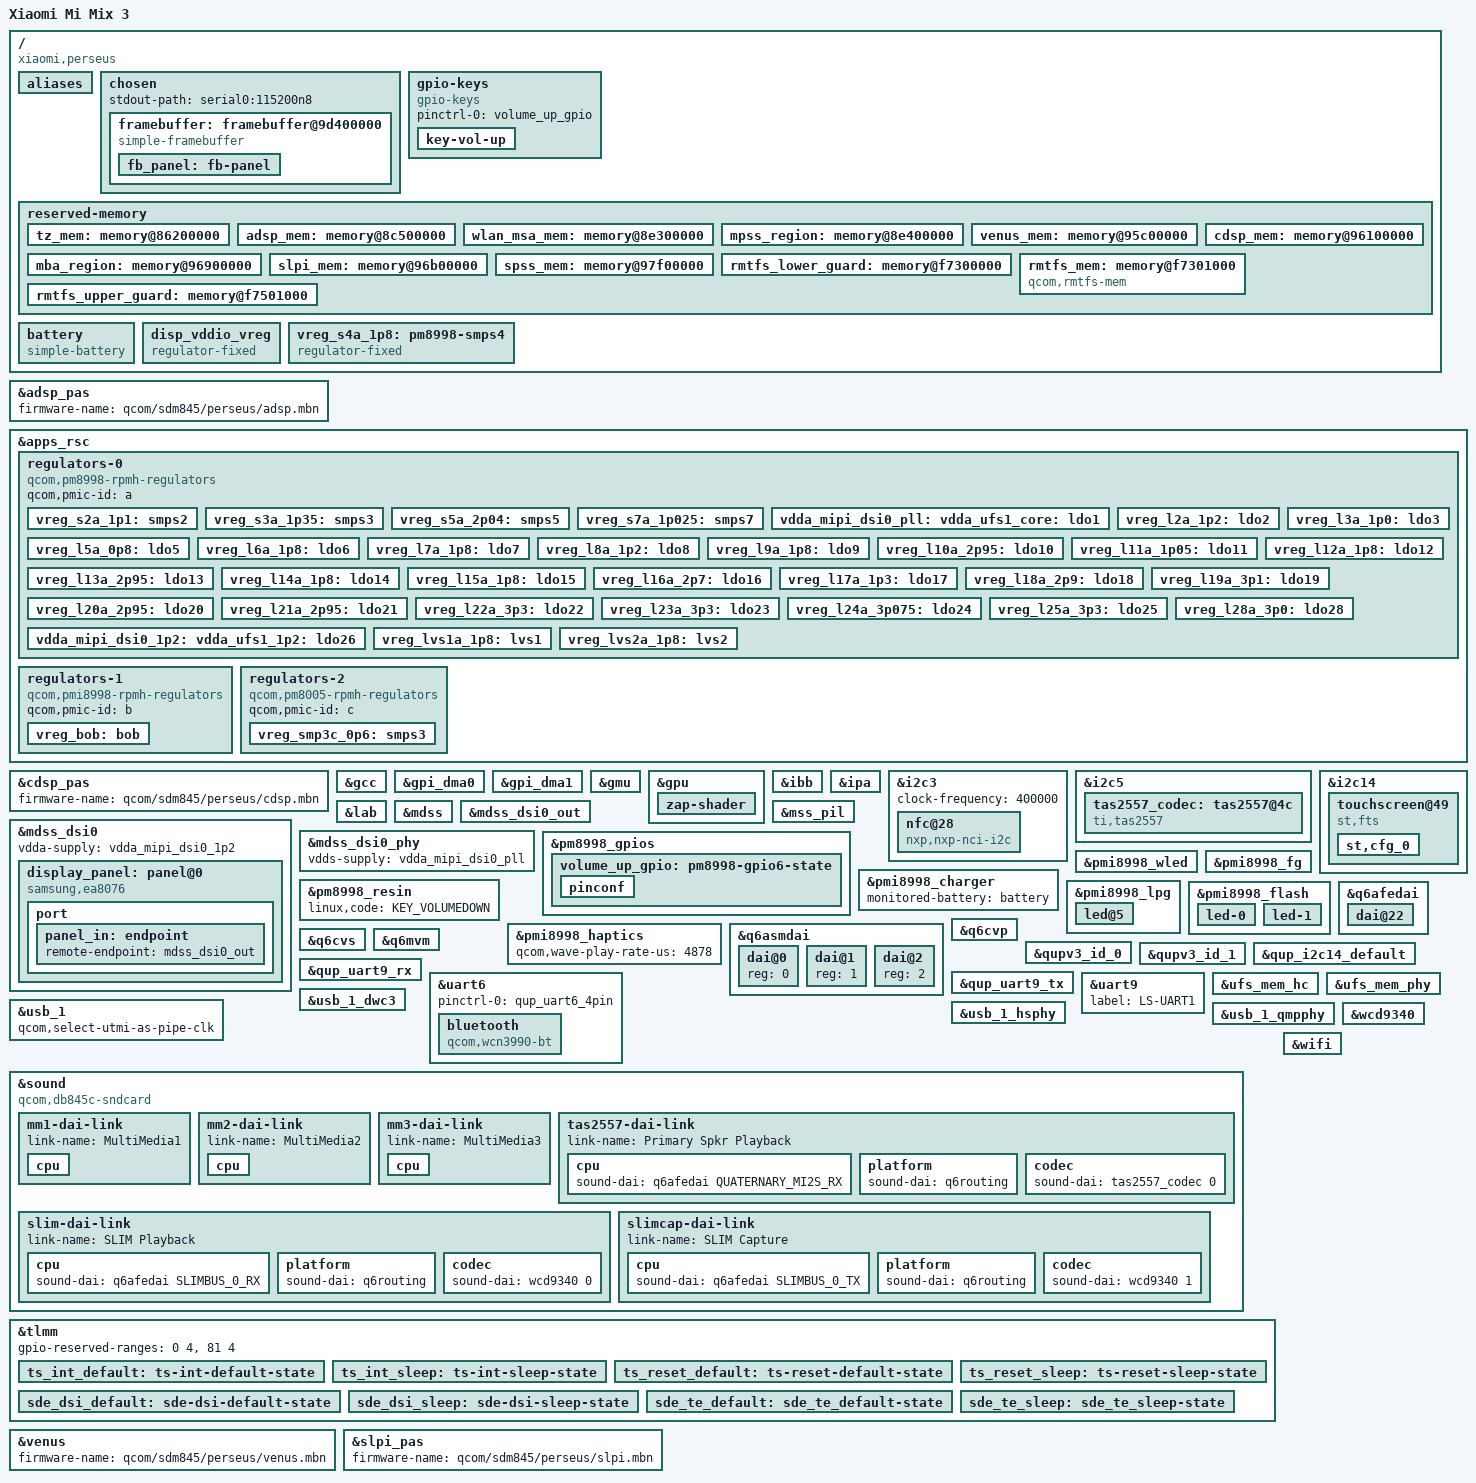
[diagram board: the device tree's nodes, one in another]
// SPDX-License-Identifier: GPL-2.0

/dts-v1/;

#include <dt-bindings/leds/common.h>
#include <dt-bindings/media/video-interfaces.h>
#include <dt-bindings/gpio/gpio.h>
#include <dt-bindings/pinctrl/qcom,pmic-gpio.h>
#include <dt-bindings/regulator/qcom,rpmh-regulator.h>
#include <dt-bindings/input/linux-event-codes.h>
#include <dt-bindings/sound/qcom,q6afe.h>
#include <dt-bindings/sound/qcom,q6asm.h>
#include <dt-bindings/sound/qcom,q6afe.h>
#include <dt-bindings/sound/qcom,q6asm.h>
#include <dt-bindings/sound/qcom,q6voice.h>

#include "sdm845.dtsi"
#include "sdm845-wcd9340.dtsi"
#include "pm8998.dtsi"
#include "pmi8998.dtsi"
#include "pm8005.dtsi"

/*
* Delete following upstream (sdm845.dtsi) reserved
* memory mappings which are different in this device.
*/
/delete-node/ &tz_mem;
/delete-node/ &adsp_mem;
/delete-node/ &wlan_msa_mem;
/delete-node/ &mpss_region;
/delete-node/ &venus_mem;
/delete-node/ &cdsp_mem;
/delete-node/ &mba_region;
/delete-node/ &slpi_mem;
/delete-node/ &spss_mem;
/delete-node/ &rmtfs_mem;

/{
	model = "Xiaomi Mi Mix 3";
	compatible = "xiaomi,perseus", "qcom,sdm845";
	chassis-type = "handset";

	/* required for bootloader to select correct board */
	qcom,board-id = <0x63 0x0>;
	qcom,msm-id = <0x141 0x20001>;

	aliases {
		serial0 = &uart9;
		serial1 = &uart6;
	};

	chosen {
		#address-cells = <2>;
		#size-cells = <2>;
		ranges;

		stdout-path = "serial0:115200n8";

		framebuffer: framebuffer@9d400000 {
			compatible = "simple-framebuffer";
			reg = <0 0x9D400000 0 0x2400000>;
			width = <1080>;
			height = <2340>;
			stride = <(1080 * 4)>;
			format = "a8r8g8b8";
			status = "okay";

			panel = <&fb_panel>;

			fb_panel: fb-panel {
				width-mm = <68>;
				height-mm = <147>;
			};
		};
	};

	gpio-keys {
		compatible = "gpio-keys";

		pinctrl-names = "default";
		pinctrl-0 = <&volume_up_gpio>;

		key-vol-up {
			label = "Volume up";
			linux,code = <KEY_VOLUMEUP>;
			gpios = <&pm8998_gpios 6 GPIO_ACTIVE_LOW>;
		};
	};

	reserved-memory {
		tz_mem: memory@86200000 {
			reg = <0 0x86200000 0 0x4900000>;
			no-map;
		};

		adsp_mem: memory@8c500000 {
			reg = <0 0x8c500000 0 0x1e00000>;
			no-map;
		};

		wlan_msa_mem: memory@8e300000 {
			reg = <0 0x8e300000 0 0x100000>;
			no-map;
		};

		mpss_region: memory@8e400000 {
			reg = <0 0x8e400000 0 0x7800000>;
			no-map;
		};

		venus_mem: memory@95c00000 {
			reg = <0 0x95c00000 0 0x500000>;
			no-map;
		};

		cdsp_mem: memory@96100000 {
			reg = <0 0x96100000 0 0x800000>;
			no-map;
		};

		mba_region: memory@96900000 {
			reg = <0 0x96900000 0 0x200000>;
			no-map;
		};

		slpi_mem: memory@96b00000 {
			reg = <0 0x96b00000 0 0x1400000>;
			no-map;
		};

		spss_mem: memory@97f00000 {
			reg = <0 0x97f00000 0 0x100000>;
			no-map;
		};

		rmtfs_lower_guard: memory@f7300000 {
			reg = <0 0xf7300000 0 0x1000>;
			no-map;
		};

		rmtfs_mem: memory@f7301000 {
			compatible = "qcom,rmtfs-mem";
			reg = <0 0xf7301000 0 0x200000>;
			no-map;

			qcom,client-id = <1>;
			qcom,vmid = <QCOM_SCM_VMID_MSS_MSA>;
		};

		rmtfs_upper_guard: memory@f7501000 {
			reg = <0 0xf7501000 0 0x1000>;
			no-map;
		};
	};

	battery: battery {
		compatible = "simple-battery";

		charge-full-design-microamp-hours = <3200000>;
		voltage-min-design-microvolt = <3700000>;
		voltage-max-design-microvolt = <4400000>;
	};

	disp_vddio_vreg: disp_vddio_vreg {
		compatible = "regulator-fixed";
		regulator-name = "disp_vddio_vreg";
		startup-delay-us = <4000>;
		regulator-always-on;
		regulator-boot-on;
		enable-active-high;
		gpio = <&tlmm 79 0>;
	};

	/*
	* Apparently RPMh does not provide support for PM8998 S4 because it
	* is always-on; model it as a fixed regulator.
	*/
	vreg_s4a_1p8: pm8998-smps4 {
		compatible = "regulator-fixed";
		regulator-name = "vreg_s4a_1p8";

		regulator-min-microvolt = <1800000>;
		regulator-max-microvolt = <1800000>;

		regulator-always-on;
	};
};

&adsp_pas {
	status = "okay";
	firmware-name = "qcom/sdm845/perseus/adsp.mbn";
};

&apps_rsc {
	regulators-0 {
		compatible = "qcom,pm8998-rpmh-regulators";
		qcom,pmic-id = "a";

		vreg_s2a_1p1: smps2 {
			regulator-always-on;
			regulator-min-microvolt = <1100000>;
			regulator-max-microvolt = <1100000>;
		};

		vreg_s3a_1p35: smps3 {
			regulator-min-microvolt = <1352000>;
			regulator-max-microvolt = <1352000>;
		};

		vreg_s5a_2p04: smps5 {
			regulator-always-on;
			regulator-min-microvolt = <1904000>;
			regulator-max-microvolt = <2040000>;
		};

		vreg_s7a_1p025: smps7 {
			regulator-always-on;
			regulator-min-microvolt = <900000>;
			regulator-max-microvolt = <1028000>;
		};

		vdda_mipi_dsi0_pll:
		vdda_ufs1_core:
		vreg_l1a_0p875: ldo1 {
			regulator-min-microvolt = <880000>;
			regulator-max-microvolt = <880000>;
			regulator-initial-mode = <RPMH_REGULATOR_MODE_HPM>;
		};

		vreg_l2a_1p2: ldo2 {
			regulator-min-microvolt = <1200000>;
			regulator-max-microvolt = <1200000>;
			regulator-initial-mode = <RPMH_REGULATOR_MODE_HPM>;
			regulator-always-on;
		};

		vreg_l3a_1p0: ldo3 {
			regulator-min-microvolt = <1000000>;
			regulator-max-microvolt = <1000000>;
			regulator-initial-mode = <RPMH_REGULATOR_MODE_HPM>;
		};

		vreg_l5a_0p8: ldo5 {
			regulator-min-microvolt = <800000>;
			regulator-max-microvolt = <800000>;
			regulator-initial-mode = <RPMH_REGULATOR_MODE_HPM>;
		};

		vreg_l6a_1p8: ldo6 {
			regulator-min-microvolt = <1856000>;
			regulator-max-microvolt = <1856000>;
			regulator-initial-mode = <RPMH_REGULATOR_MODE_HPM>;
		};

		vreg_l7a_1p8: ldo7 {
			regulator-min-microvolt = <1800000>;
			regulator-max-microvolt = <1800000>;
			regulator-initial-mode = <RPMH_REGULATOR_MODE_HPM>;
		};

		vreg_l8a_1p2: ldo8 {
			regulator-min-microvolt = <1200000>;
			regulator-max-microvolt = <1248000>;
			regulator-initial-mode = <RPMH_REGULATOR_MODE_HPM>;
		};

		vreg_l9a_1p8: ldo9 {
			regulator-min-microvolt = <1704000>;
			regulator-max-microvolt = <2928000>;
			regulator-initial-mode = <RPMH_REGULATOR_MODE_HPM>;
		};

		vreg_l10a_2p95: ldo10 {
			regulator-min-microvolt = <1704000>;
			regulator-max-microvolt = <2928000>;
			regulator-initial-mode = <RPMH_REGULATOR_MODE_HPM>;
		};

		vreg_l11a_1p05: ldo11 {
			regulator-min-microvolt = <1000000>;
			regulator-max-microvolt = <1048000>;
			regulator-initial-mode = <RPMH_REGULATOR_MODE_HPM>;
		};

		vreg_l12a_1p8: ldo12 {
			regulator-min-microvolt = <1800000>;
			regulator-max-microvolt = <1800000>;
			regulator-initial-mode = <RPMH_REGULATOR_MODE_HPM>;
		};

		vreg_l13a_2p95: ldo13 {
			regulator-min-microvolt = <1800000>;
			regulator-max-microvolt = <2960000>;
			regulator-initial-mode = <RPMH_REGULATOR_MODE_HPM>;
		};

		vreg_l14a_1p8: ldo14 {
			regulator-min-microvolt = <1800000>;
			regulator-max-microvolt = <1800000>;
			regulator-always-on;
			regulator-boot-on;
			regulator-initial-mode = <RPMH_REGULATOR_MODE_HPM>;
		};

		vreg_l15a_1p8: ldo15 {
			regulator-min-microvolt = <1800000>;
			regulator-max-microvolt = <1800000>;
			regulator-initial-mode = <RPMH_REGULATOR_MODE_HPM>;
		};

		vreg_l16a_2p7: ldo16 {
			regulator-min-microvolt = <2704000>;
			regulator-max-microvolt = <2704000>;
			regulator-initial-mode = <RPMH_REGULATOR_MODE_HPM>;
		};

		vreg_l17a_1p3: ldo17 {
			regulator-always-on;
			regulator-min-microvolt = <1304000>;
			regulator-max-microvolt = <1304000>;
			regulator-initial-mode = <RPMH_REGULATOR_MODE_HPM>;
		};

		vreg_l18a_2p9: ldo18 {
			regulator-min-microvolt = <2704000>;
			regulator-max-microvolt = <2960000>;
			regulator-initial-mode = <RPMH_REGULATOR_MODE_HPM>;
		};

		vreg_l19a_3p1: ldo19 {
			regulator-min-microvolt = <2856000>;
			regulator-max-microvolt = <3104000>;
			regulator-initial-mode = <RPMH_REGULATOR_MODE_HPM>;
		};

		vreg_l20a_2p95: ldo20 {
			regulator-min-microvolt = <2704000>;
			regulator-max-microvolt = <2960000>;
			regulator-initial-mode = <RPMH_REGULATOR_MODE_HPM>;
		};

		vreg_l21a_2p95: ldo21 {
			regulator-min-microvolt = <2704000>;
			regulator-max-microvolt = <2960000>;
			regulator-initial-mode = <RPMH_REGULATOR_MODE_HPM>;
		};

		vreg_l22a_3p3: ldo22 {
			regulator-min-microvolt = <2864000>;
			regulator-max-microvolt = <3312000>;
			regulator-initial-mode = <RPMH_REGULATOR_MODE_HPM>;
		};

		vreg_l23a_3p3: ldo23 {
			regulator-min-microvolt = <3000000>;
			regulator-max-microvolt = <3312000>;
			regulator-initial-mode = <RPMH_REGULATOR_MODE_HPM>;
		};

		vreg_l24a_3p075: ldo24 {
			regulator-min-microvolt = <3088000>;
			regulator-max-microvolt = <3088000>;
			regulator-initial-mode = <RPMH_REGULATOR_MODE_HPM>;
		};

		vreg_l25a_3p3: ldo25 {
			regulator-always-on;
			regulator-min-microvolt = <3000000>;
			regulator-max-microvolt = <3312000>;
			regulator-initial-mode = <RPMH_REGULATOR_MODE_HPM>;
		};

		vdda_mipi_dsi0_1p2:
		vdda_ufs1_1p2:
		vreg_l26a_1p2: ldo26 {
			regulator-min-microvolt = <1200000>;
			regulator-max-microvolt = <1200000>;
			regulator-initial-mode = <RPMH_REGULATOR_MODE_HPM>;
			regulator-boot-on;
		};

		vreg_l28a_3p0: ldo28 {
			regulator-min-microvolt = <2856000>;
			regulator-max-microvolt = <3008000>;
			regulator-initial-mode = <RPMH_REGULATOR_MODE_HPM>;
			regulator-always-on;
		};

		vreg_lvs1a_1p8: lvs1 {
			regulator-min-microvolt = <1800000>;
			regulator-max-microvolt = <1800000>;
			regulator-always-on;
		};

		vreg_lvs2a_1p8: lvs2 {
			regulator-min-microvolt = <1800000>;
			regulator-max-microvolt = <1800000>;
			regulator-always-on;
		};
	};

	regulators-1 {
		compatible = "qcom,pmi8998-rpmh-regulators";
		qcom,pmic-id = "b";

		vreg_bob: bob {
			regulator-min-microvolt = <3312000>;
			regulator-max-microvolt = <3600000>;
			regulator-initial-mode = <RPMH_REGULATOR_MODE_AUTO>;
			regulator-allow-bypass;
		};
	};

	regulators-2 {
		compatible = "qcom,pm8005-rpmh-regulators";
		qcom,pmic-id = "c";

		vreg_smp3c_0p6: smps3 {
			regulator-min-microvolt = <600000>;
			regulator-max-microvolt = <600000>;
		};
	};
};

&cdsp_pas {
	status = "okay";
	firmware-name = "qcom/sdm845/perseus/cdsp.mbn";
};


&gcc {
	protected-clocks = <GCC_QSPI_CORE_CLK>,
				<GCC_QSPI_CORE_CLK_SRC>,
				<GCC_QSPI_CNOC_PERIPH_AHB_CLK>,
				<GCC_LPASS_Q6_AXI_CLK>,
				<GCC_LPASS_SWAY_CLK>;
};

&gpi_dma0 {
	status = "okay";
};

&gpi_dma1 {
	status = "okay";
};

&gmu {
	status = "okay";
};

&gpu {
	status = "okay";

	zap-shader {
		memory-region = <&gpu_mem>;
		firmware-name = "qcom/sdm845/perseus/a630_zap.mbn";
	};
};

&ibb {
	regulator-min-microvolt = <4600000>;
	regulator-max-microvolt = <6000000>;
	regulator-over-current-protection;
	regulator-pull-down;
	regulator-soft-start;
	qcom,discharge-resistor-kohms = <300>;
};

&ipa {
	qcom,gsi-loader = "self";
	memory-region = <&ipa_fw_mem>;
	firmware-name = "qcom/sdm845/perseus/ipa_fws.mbn";
	status = "okay";
};

&i2c3 {
	status = "okay";
	clock-frequency = <400000>;

	nfc@28 {
		compatible = "nxp,nxp-nci-i2c";
		reg = <0x28>;

		interrupt-parent = <&tlmm>;
		interrupts = <63 IRQ_TYPE_LEVEL_HIGH>;

		enable-gpios = <&tlmm 128 GPIO_ACTIVE_HIGH>;
		firmware-gpios = <&tlmm 88 GPIO_ACTIVE_HIGH>;

		//qcom,nq-irq = <0x34 0x3f 0x00>;
		//qcom,nq-ven = <0x34 0x80 0x00>;
		//qcom,nq-firm = <0x34 0x58 0x00>;
		//qcom,nq-clkreq = <0xe6 0x15 0x00>;
		//qcom,nq-esepwr = <0x34 0x74 0x00>;
	};
};

&i2c5 {
	#dma-cells = <3>;
	status = "okay";

	dmas =  <&gpi_dma0 0 5 QCOM_GPI_I2C>,
			<&gpi_dma0 1 5 QCOM_GPI_I2C>;
	dma-names = "tx", "rx";
	tas2557_codec: tas2557@4c{
		#sound-dai-cells = <1>;
		compatible = "ti,tas2557";
		reg = <0x4c>;
		ti,cdc-reset-gpio = <&tlmm 69 0>;
		ti,irq-gpio = <&tlmm 30 0>;
		ti,i2s-bits = <16>;
		ti,bypass-tmax = <0>;
	};
};

&i2c14 {
	#dma-cells = <3>;
	status = "okay";
	clock-frequency = <400000>;

	dmas =  <&gpi_dma1 0 6 QCOM_GPI_I2C>,
			<&gpi_dma1 1 6 QCOM_GPI_I2C>;
	dma-names = "tx", "rx";

	touchscreen@49 {
		compatible = "st,fts";
		reg = <0x49>;
		interrupts-extended = <&tlmm 31 0x2008>;

		pinctrl-names = "default", "sleep";
		pinctrl-0 = <&ts_int_default &ts_reset_default>;
		pinctrl-1 = <&ts_int_sleep &ts_reset_sleep>;

		vdd-supply = <&disp_vddio_vreg>;
		avdd-supply = <&vreg_l28a_3p0>;

		st,pwr-reg-name = "avdd";
		st,bus-reg-name = "vdd";
		st,regulator_dvdd = "vdd";
		st,regulator_avdd = "avdd";
		st,irq-gpio = <&tlmm 31 0x2008>;
		st,irq-gpio-name = "fts_irq";
		st,reset-gpio-enable;
		st,reset-gpio = <&tlmm 32 0x00>;
		st,max-coords = <1079 2339>;
		st,reset-gpio-name = "fts_rst";
		st,irq-flags = <0x2008>;
		st,key-num = <2>;
		st,key-codes = <158 139>;
		st,config-array-size = <1>;
		st,default-fw-name = "st_fts_e5.ftb";

		st,cfg_0 {
			st,tp-vendor = <0x52>;
			st,fw-name = "st_fts_e5.ftb";
			st,limit-name = "stm_fts_production_limits.csv";
		};
	};
};

&lab {
	regulator-min-microvolt = <4600000>;
	regulator-max-microvolt = <6000000>;
	regulator-soft-start;
	regulator-pull-down;
};

&mdss {
	status = "okay";
};

&mdss_dsi0 {
	status = "okay";
	vdda-supply = <&vdda_mipi_dsi0_1p2>;

	#address-cells = <1>;
	#size-cells = <0>;

	display_panel: panel@0 {
		status = "okay";
		compatible = "samsung,ea8076";
		#address-cells = <1>;
		#size-cells = <0>;
		reg = <0>;

		reset-gpios = <&tlmm 6 GPIO_ACTIVE_LOW>;
		vddio-supply = <&vreg_l14a_1p8>;
		backlight = <&pmi8998_wled>;
		vddpos-supply = <&lab>;
		vddneg-supply = <&ibb>;

		pinctrl-names = "default", "sleep";
		pinctrl-0 = <&sde_dsi_default &sde_te_default>;
		pinctrl-1 = <&sde_dsi_sleep &sde_te_sleep>;

		port {
			panel_in: endpoint {
				remote-endpoint = <&mdss_dsi0_out>;
			};
		};
	};
};

&mdss_dsi0_out {
	remote-endpoint = <&panel_in>;
	data-lanes = <0 1 2 3>;
};

&mdss_dsi0_phy {
	status = "okay";
	vdds-supply = <&vdda_mipi_dsi0_pll>;
};

&mss_pil {
	status = "okay";
	firmware-name = "qcom/sdm845/perseus/mba.mbn", "qcom/sdm845/perseus/modem.mbn";
};

&pm8998_gpios {
	volume_up_gpio: pm8998-gpio6-state {
		pinconf {
			qcom,drive-strength = <PMIC_GPIO_STRENGTH_NO>;
			function = "normal";
			pins = "gpio6";
			input-enable;
			bias-pull-up;
		};
	};
};

&pmi8998_wled {
	status = "okay";
	qcom,current-boost-limit = <970>;
	qcom,ovp-millivolt = <29600>;
	qcom,current-limit-microamp = <20000>;
	qcom,num-strings = <2>;
	qcom,switching-freq = <600>;
	qcom,external-pfet;
	qcom,cabc;
};

&pmi8998_charger {
	monitored-battery = <&battery>;

	status = "okay";
};

&pmi8998_fg {
	status = "okay";

	power-supplies = <&pmi8998_charger>;
	monitored-battery = <&battery>;
};

&pm8998_resin {
	linux,code = <KEY_VOLUMEDOWN>;
	status = "okay";
};

&pmi8998_lpg {
	status = "okay";

	led@5 {
		reg = <5>;
		color = <LED_COLOR_ID_WHITE>;
		function = LED_FUNCTION_STATUS;
	};
};

&pmi8998_flash {
	status = "okay";

	led-0 {
		function = LED_FUNCTION_FLASH;
		color = <LED_COLOR_ID_WHITE>;
		led-sources = <1>;
		led-max-microamp = <500000>;
		flash-max-microamp = <1500000>;
		flash-max-timeout-us = <1280000>;
	};

	led-1 {
		function = LED_FUNCTION_FLASH;
		color = <LED_COLOR_ID_YELLOW>;
		led-sources = <2>;
		led-max-microamp = <500000>;
		flash-max-microamp = <1500000>;
		flash-max-timeout-us = <1280000>;
	};
};

&pmi8998_haptics {
	status = "okay";
	qcom,wave-play-rate-us = <4878>;
};

&q6afedai {
	dai@22 {
		reg = <QUATERNARY_MI2S_RX>;
		qcom,sd-lines = <0>;
	};
};

&q6asmdai {
	dai@0 {
		reg = <0>;
	};

	dai@1 {
		reg = <1>;
	};

	dai@2 {
		reg = <2>;
	};
};

&q6cvp {
	status = "okay";
};

&q6cvs {
	status = "okay";
};

&q6mvm {
	status = "okay";
};

&qupv3_id_0 {
	status = "okay";
};

&qupv3_id_1 {
	status = "okay";
};

&qup_i2c14_default {
	drive-strength = <2>;
	bias-disable;
};

&qup_uart9_rx {
	drive-strength = <2>;
	bias-pull-up;
};

&qup_uart9_tx {
	drive-strength = <2>;
	bias-disable;
};

&uart6 {
	status = "okay";

	pinctrl-0 = <&qup_uart6_4pin>;

	bluetooth {
		compatible = "qcom,wcn3990-bt";

		firmware-name = "perseus/crnv21.bin";

		vddio-supply = <&vreg_s4a_1p8>;
		vddxo-supply = <&vreg_l7a_1p8>;
		vddrf-supply = <&vreg_l17a_1p3>;
		vddch0-supply = <&vreg_l25a_3p3>;
		max-speed = <3200000>;
	};
};

&uart9 {
	label = "LS-UART1";
	status = "okay";
};

&ufs_mem_hc {
	status = "okay";

	reset-gpios = <&tlmm 150 GPIO_ACTIVE_LOW>;

	vcc-supply = <&vreg_l20a_2p95>;
	vcc-max-microamp = <600000>;
};

&ufs_mem_phy {
	status = "okay";

	vdda-phy-supply = <&vdda_ufs1_core>;
	vdda-pll-supply = <&vdda_ufs1_1p2>;
};

&usb_1 {
	status = "okay";

	/*
	* disable USB3 clock requirement as the device only supports
	* USB2.
	*/
	qcom,select-utmi-as-pipe-clk;
};

&usb_1_dwc3 {
	/*
	* We don't have the capability to switch modes yet.
	*/
	dr_mode = "peripheral";

	/* fastest mode for USB 2 */
	maximum-speed = "high-speed";

	/* Remove USB3 phy as it's unused on this device. */
	phys = <&usb_1_hsphy>;
	phy-names = "usb2-phy";
};

&usb_1_hsphy {
	status = "okay";

	vdd-supply = <&vreg_l1a_0p875>;
	vdda-pll-supply = <&vreg_l12a_1p8>;
	vdda-phy-dpdm-supply = <&vreg_l24a_3p075>;

	qcom,imp-res-offset-value = <8>;
	qcom,hstx-trim-value = <QUSB2_V2_HSTX_TRIM_21_6_MA>;
	qcom,preemphasis-level = <QUSB2_V2_PREEMPHASIS_5_PERCENT>;
	qcom,preemphasis-width = <QUSB2_V2_PREEMPHASIS_WIDTH_HALF_BIT>;
};

&usb_1_qmpphy {
	status = "okay";

	vdda-phy-supply = <&vreg_l26a_1p2>;
	vdda-pll-supply = <&vreg_l1a_0p875>;
};

&sound {
	compatible = "qcom,db845c-sndcard";
	pinctrl-0 = <&quat_mi2s_active &quat_mi2s_sd0_active>;
	pinctrl-names = "default";
	model = "Xiaomi MIX 3";
	audio-routing =
		"RX_BIAS", "MCLK",
		"AMIC1", "MIC BIAS1",
		"AMIC2", "MIC BIAS2",
		"AMIC3", "MIC BIAS3";

	mm1-dai-link {
		link-name = "MultiMedia1";
		cpu {
			sound-dai = <&q6asmdai MSM_FRONTEND_DAI_MULTIMEDIA1>;
		};
	};

	mm2-dai-link {
		link-name = "MultiMedia2";
		cpu {
			sound-dai = <&q6asmdai MSM_FRONTEND_DAI_MULTIMEDIA2>;
		};
	};

	mm3-dai-link {
		link-name = "MultiMedia3";
		cpu {
			sound-dai = <&q6asmdai MSM_FRONTEND_DAI_MULTIMEDIA3>;
		};
	};

	tas2557-dai-link {
		link-name = "Primary Spkr Playback";
		cpu {
			sound-dai = <&q6afedai QUATERNARY_MI2S_RX>;
		};

		platform {
			sound-dai = <&q6routing>;
		};

		codec {
			sound-dai = <&tas2557_codec 0>;
		};
	};

	slim-dai-link {
		link-name = "SLIM Playback";
		cpu {
			sound-dai = <&q6afedai SLIMBUS_0_RX>;
		};

		platform {
			sound-dai = <&q6routing>;
		};

		codec {
			sound-dai = <&wcd9340 0>;
		};
	};

	slimcap-dai-link {
		link-name = "SLIM Capture";
		cpu {
			sound-dai = <&q6afedai SLIMBUS_0_TX>;
		};

		platform {
			sound-dai = <&q6routing>;
		};

		codec {
			sound-dai = <&wcd9340 1>;
		};
	};
};

&tlmm {
	gpio-reserved-ranges = <0 4>, <81 4>;

	ts_int_default: ts-int-default-state {
		pins = "gpio31";
		function = "gpio";
		drive-strength = <16>;
		bias-pull-down;
		input-enable;
	};

	ts_int_sleep: ts-int-sleep-state {
		pins = "gpio31";
		function = "gpio";
		drive-strength = <2>;
		bias-pull-down;
		input-enable;
	};

	ts_reset_default: ts-reset-default-state {
		pins = "gpio32";
		function = "gpio";
		drive-strength = <16>;
		output-high;
	};

	ts_reset_sleep: ts-reset-sleep-state {
		pins = "gpio32";
		function = "gpio";
		drive-strength = <2>;
		bias-disable;
		output-low;
	};

	sde_dsi_default: sde-dsi-default-state {
		pins = "gpio6", "gpio52";
		function = "gpio";
		drive-strength = <8>;
		bias-disable;
	};

	sde_dsi_sleep: sde-dsi-sleep-state {
		pins = "gpio6", "gpio52";
		function = "gpio";
		drive-strength = <2>;
		bias-pull-down;
	};

	sde_te_default: sde_te_default-state {
		pins = "gpio10";
		function = "mdp_vsync";
		drive-strength = <2>;
		bias-pull-down;
	};

	sde_te_sleep: sde_te_sleep-state {
		pins = "gpio10";
		function = "mdp_vsync";
		drive-strength = <2>;
		bias-pull-down;
	};
};

&venus {
	firmware-name = "qcom/sdm845/perseus/venus.mbn";
	status = "okay";
};

&wcd9340 {
	reset-gpios = <&tlmm 64 GPIO_ACTIVE_HIGH>;
	vdd-buck-sido-supply = <&vreg_s4a_1p8>;
	vdd-buck-supply = <&vreg_s4a_1p8>;
	vdd-tx-supply = <&vreg_s4a_1p8>;
	vdd-rx-supply = <&vreg_s4a_1p8>;
	vdd-io-supply = <&vreg_s4a_1p8>;

	qcom,micbias1-microvolt = <2700000>;
	qcom,micbias2-microvolt = <1800000>;
	qcom,micbias3-microvolt = <2700000>;
	qcom,micbias4-microvolt = <2700000>;
};

&wifi {
	status = "okay";
	vdd-0.8-cx-mx-supply = <&vreg_l5a_0p8>;
	vdd-1.8-xo-supply = <&vreg_l7a_1p8>;
	vdd-1.3-rfa-supply = <&vreg_l17a_1p3>;
	vdd-3.3-ch0-supply = <&vreg_l25a_3p3>;
	vdd-3.3-ch1-supply = <&vreg_l23a_3p3>;

	qcom,snoc-host-cap-skip-quirk;
	qcom,ath10k-calibration-variant = "xiaomi_perseus";
};

&slpi_pas {
	firmware-name = "qcom/sdm845/perseus/slpi.mbn";
	status = "okay";
};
